# AE822FA0E5597BS0_CM55_HP_View register map
Vendor: Alif Semiconductor; Series: E8; File version: 1.0
CPU: CM55 r1p0, selectable endian, MPU, FPU, double-precision FPU, DSP, VTOR, 8 interrupt priority bits, 1 SAU regions
Registers are 32-bit, read-write, reset 0x0 unless marked. A register's access mark holds for its fields unless they carry their own. Offsets are from the block's base; [hi:lo] are bit positions; {n}, {i} and the like mark numbered series.

## AES0
Base 0x83001000
Same registers: AES1 0x83003000
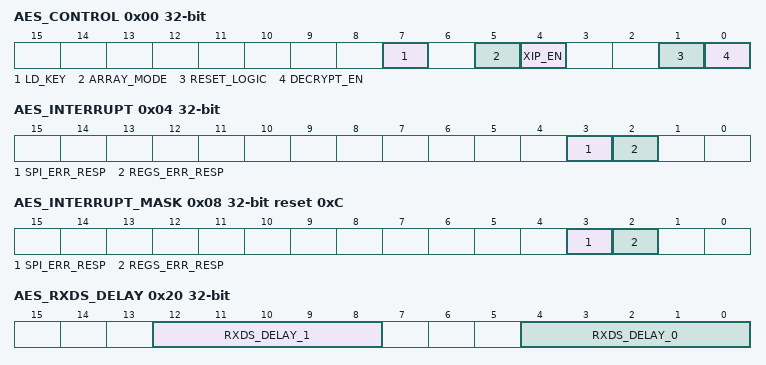
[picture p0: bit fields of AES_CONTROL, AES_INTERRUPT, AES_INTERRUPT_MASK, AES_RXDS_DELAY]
0x00 AES_CONTROL
  [7] LD_KEY — Write 1 once the new key has been written by the Secure Enclave, so the key can be pre-processed by the AES engine. Read returns 0x0.
  [5] ARRAY_MODE — If 0x1, the address presented to the OSPI logic will be mapped to {ADDR[25:4], 6'h0, ADDR[3:0]} to accommodate memories that use this addressing protocol.
  [4] XIP_EN — When this bit is set, the OSPI can be used in XIP mode directly, with or without intervention from the decryption logic.
  [1] RESET_LOGIC — Reset the AES engine.
  [0] DECRYPT_EN — Decryption Enabled When set, this bit causes host read accesses to use the decryption logic rather than go directly to the OSPI module. Note that the OSPI module must be programmed to work in XIP mode prior to setting this bit.
0x04 AES_INTERRUPT — AES Interrupt Control Register
  [3] SPI_ERR_RESP — SPI Error Response interrupt enabling. Set when an error response is received from the OSPI through the AHB bus. Write 1 to clear bit.
    0=SPI Error Response interrupt is disabled; 1=SPI Error Response interrupt is enabled
  [2] REGS_ERR_RESP — Register Error Response interrupt enabling. Set when there is an access to an invalid AES register. Write 1 to clear bit.
    0=Register Error Response interrupt is disabled; 1=Register Error Response interrupt is enabled
0x08 AES_INTERRUPT_MASK reset 0xC
  [3] SPI_ERR_RESP — Mask for the SPI Error Response interrupt.
    0=SPI Error Response interrupt is not masked; 1=SPI Error Response interrupt is masked
  [2] REGS_ERR_RESP — Mask for the Register Error Response interrupt.
    0=Register Error Response interrupt is not masked; 1=Register Error Response interrupt is masked
0x08 AES_CLK_DIS (alternate view of AES_INTERRUPT_MASK) — AES Clock Disable Register
  [0] AES_CLK_DIS — Disable the clock to the AES decryption engine.
0x20 AES_RXDS_DELAY — OSPI RXDS Delay Register
  [12:8] RXDS_DELAY_1 — A delay added to the OSPI RXDS[1] input signal. Each increment adds approximately 350 ps to the delay. The maximum value is 23.
  [4:0] RXDS_DELAY_0 — A delay added to the OSPI RXDS[0] input signal. Each increment adds approximately 350 ps to the delay. The maximum value is 23.
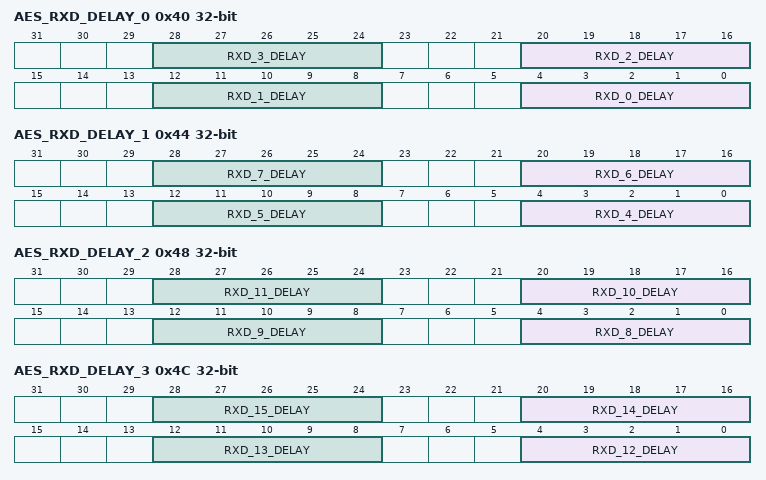
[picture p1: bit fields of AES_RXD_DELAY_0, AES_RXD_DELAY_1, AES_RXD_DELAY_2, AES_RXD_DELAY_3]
0x40 AES_RXD_DELAY_0 — OSPI RXD[3:0] Delay Register
  [8n+4:8n] RXD_{n}_DELAY (n=0..3) — A delay added to the RXD[{n}] input signal. Each increment adds approximately 350 ps to the delay. The maximum value is 23.
0x44 AES_RXD_DELAY_1 — OSPI RXD[7:4] Delay Register
  [8n-28:8n-32] RXD_{n}_DELAY (n=4..7) — A delay added to the RXD[{n}] input signal. Each increment adds approximately 350 ps to the delay. The maximum value is 23.
0x48 AES_RXD_DELAY_2 — OSPI RXD[11:8] Delay Register
  [8n-60:8n-64] RXD_{n}_DELAY (n=8..11) — A delay added to the RXD[{n}] input signal. Each increment adds approximately 350 ps to the delay. The maximum value is 23.
0x4C AES_RXD_DELAY_3 — OSPI RXD[15:12] Delay Register
  [8n-92:8n-96] RXD_{n}_DELAY (n=12..15) — A delay added to the RXD[{n}] input signal. Each increment adds approximately 350 ps to the delay. The maximum value is 23.
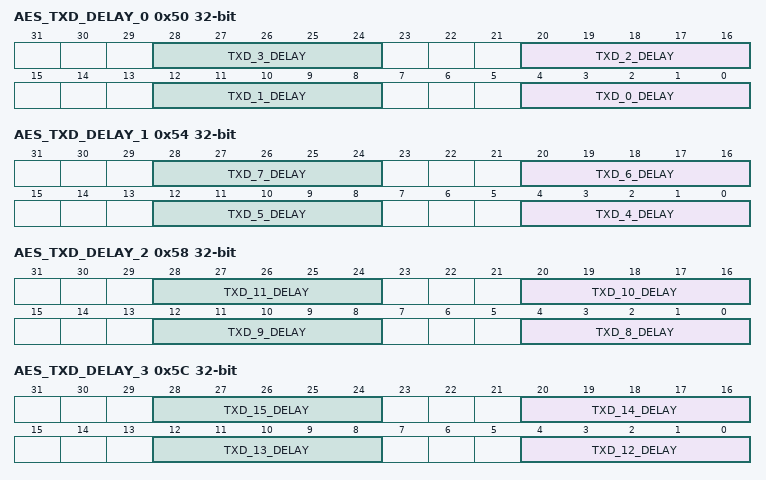
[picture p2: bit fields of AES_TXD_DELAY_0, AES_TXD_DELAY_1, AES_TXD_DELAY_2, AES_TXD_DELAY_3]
0x50 AES_TXD_DELAY_0 — OSPI TXD[3:0] Delay Register
  [8n+4:8n] TXD_{n}_DELAY (n=0..3) — A delay added to the TXD[{n}] output signal. Each increment adds approximately 350 ps to the delay. The maximum value is 23.
0x54 AES_TXD_DELAY_1 — OSPI TXD[7:4] Delay Register
  [8n-28:8n-32] TXD_{n}_DELAY (n=4..7) — A delay added to the TXD[{n}] output signal. Each increment adds approximately 350 ps to the delay. The maximum value is 23.
0x58 AES_TXD_DELAY_2 — OSPI TXD[11:8] Delay Register
  [8n-60:8n-64] TXD_{n}_DELAY (n=8..11) — A delay added to the TXD[{n}] output signal. Each increment adds approximately 350 ps to the delay. The maximum value is 23.
0x5C AES_TXD_DELAY_3 — OSPI TXD[15:12] Delay Register
  [8n-92:8n-96] TXD_{n}_DELAY (n=12..15) — A delay added to the TXD[{n}] output signal. Each increment adds approximately 350 ps to the delay. The maximum value is 23.
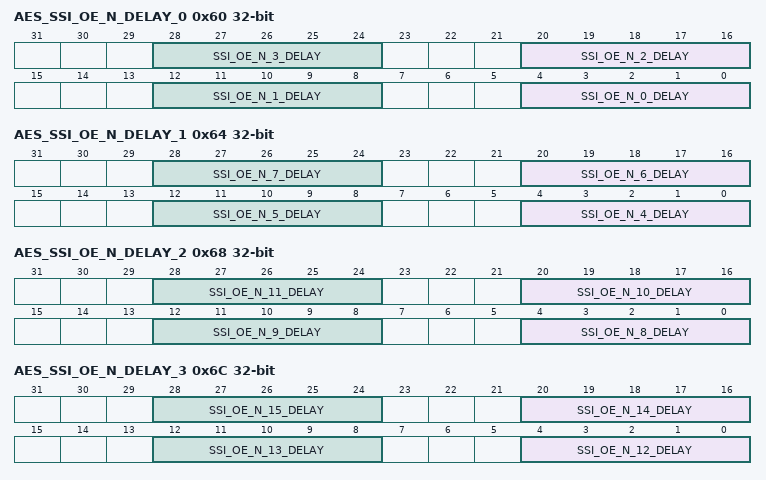
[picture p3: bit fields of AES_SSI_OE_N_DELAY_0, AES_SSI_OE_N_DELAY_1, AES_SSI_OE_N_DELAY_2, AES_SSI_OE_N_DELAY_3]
0x60 AES_SSI_OE_N_DELAY_0 — OSPI SSI_OE_N[3:0] Delay Register
  [8n+4:8n] SSI_OE_N_{n}_DELAY (n=0..3) — A delay added to the SSI_OE_N[{n}] output signal. Each increment adds approximately 350 ps to the delay. The maximum value is 23.
0x64 AES_SSI_OE_N_DELAY_1 — OSPI SSI_OE_N[7:4] Delay Register
  [8n-28:8n-32] SSI_OE_N_{n}_DELAY (n=4..7) — A delay added to the SSI_OE_N[{n}] output signal. Each increment adds approximately 350 ps to the delay. The maximum value is 23.
0x68 AES_SSI_OE_N_DELAY_2 — OSPI SSI_OE_N[11:8] Delay Register
  [8n-60:8n-64] SSI_OE_N_{n}_DELAY (n=8..11) — A delay added to the SSI_OE_N[{n}] output signal. Each increment adds approximately 350 ps to the delay. The maximum value is 23.
0x6C AES_SSI_OE_N_DELAY_3 — OSPI SSI_OE_N[15:12] Delay Register
  [8n-92:8n-96] SSI_OE_N_{n}_DELAY (n=12..15) — A delay added to the SSI_OE_N[{n}] output signal. Each increment adds approximately 350 ps to the delay. The maximum value is 23.
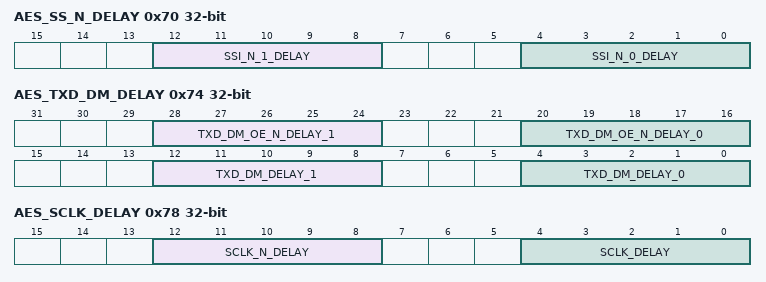
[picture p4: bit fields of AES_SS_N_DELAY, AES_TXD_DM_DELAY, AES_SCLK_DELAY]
0x70 AES_SS_N_DELAY — OSPI SS_N Delay Register
  [12:8] SSI_N_1_DELAY — A delay added to the SSI_N[1] output signal. Each increment adds approximately 350 ps to the delay. The maximum value is 23.
  [4:0] SSI_N_0_DELAY — A delay added to the SSI_N[0] output signal. Each increment adds approximately 350 ps to the delay. The maximum value is 23.
0x74 AES_TXD_DM_DELAY — OSPI TXD_DM Delay Register
  [28:24] TXD_DM_OE_N_DELAY_1 — A delay added to the TXD_DM_OE_N[1] output signal. Each increment adds approximately 350 ps to the delay. The maximum value is 23.
  [20:16] TXD_DM_OE_N_DELAY_0 — A delay added to the TXD_DM_OE_N[0] output signal. Each increment adds approximately 350 ps to the delay. The maximum value is 23.
  [12:8] TXD_DM_DELAY_1 — A delay added to the TXD_DM[1] output signal. Each increment adds approximately 350 ps to the delay. The maximum value is 23.
  [4:0] TXD_DM_DELAY_0 — A delay added to the TXD_DM[0] output signal. Each increment adds approximately 350 ps to the delay. The maximum value is 23.
0x78 AES_SCLK_DELAY — OSPI SLCK Delay Register
  [12:8] SCLK_N_DELAY — A delay added to the SCLK_N output signal. Each increment adds approximately 350 ps to the delay. The maximum value is 23.
  [4:0] SCLK_DELAY — A delay added to the SCLK output signal. Each increment adds approximately 350 ps to the delay. The maximum value is 23.
